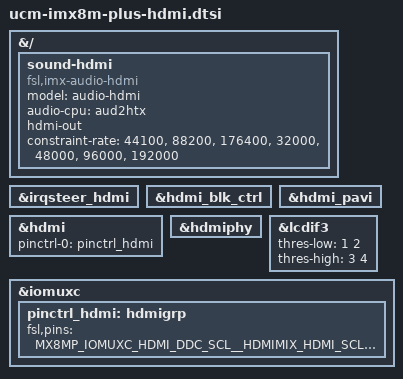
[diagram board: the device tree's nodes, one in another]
/*
 * Copyright 2024 CompuLab
 *
 * This program is free software; you can redistribute it and/or
 * modify it under the terms of the GNU General Public License
 * as published by the Free Software Foundation; either version 2
 * of the License, or (at your option) any later version.
 *
 * This program is distributed in the hope that it will be useful,
 * but WITHOUT ANY WARRANTY; without even the implied warranty of
 * MERCHANTABILITY or FITNESS FOR A PARTICULAR PURPOSE.  See the
 * GNU General Public License for more details.
 */

&{/} {
	sound-hdmi {
		compatible = "fsl,imx-audio-hdmi";
		model = "audio-hdmi";
		audio-cpu = <&aud2htx>;
		hdmi-out;
		constraint-rate = <44100>,
				<88200>,
				<176400>,
				<32000>,
				<48000>,
				<96000>,
				<192000>;
		status = "okay";
	};
};

&irqsteer_hdmi {
	status = "okay";
};

&hdmi_blk_ctrl {
	status = "okay";
};

&hdmi_pavi {
	status = "okay";
};

&hdmi {
	pinctrl-names = "default";
	pinctrl-0 = <&pinctrl_hdmi>;
	status = "okay";
};

&hdmiphy {
	status = "okay";
};

&lcdif3 {
	status = "okay";

	thres-low  = <1 2>; /* (FIFO * 1 / 2) */
	thres-high = <3 4>; /* (FIFO * 3 / 4) */
};

&iomuxc {
	pinctrl_hdmi: hdmigrp {
		fsl,pins = <
			MX8MP_IOMUXC_HDMI_DDC_SCL__HDMIMIX_HDMI_SCL	0x400001c3
			MX8MP_IOMUXC_HDMI_DDC_SDA__HDMIMIX_HDMI_SDA	0x400001c3
			MX8MP_IOMUXC_HDMI_HPD__HDMIMIX_HDMI_HPD		0x40000019
			MX8MP_IOMUXC_HDMI_CEC__HDMIMIX_HDMI_CEC		0x40000019
		>;
	};
};
